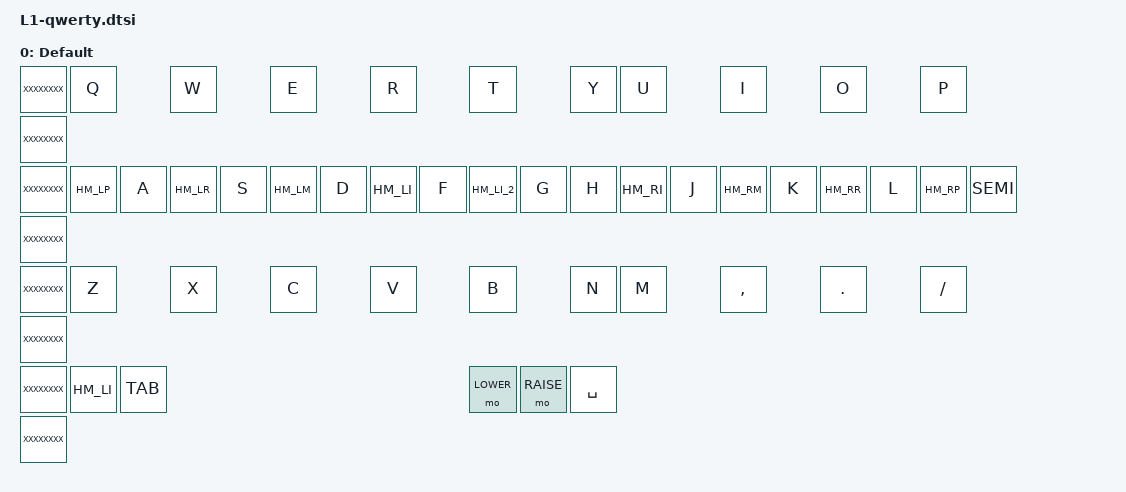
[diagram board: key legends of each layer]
/**
 *
 */

/ {
  keymap {
    compatible = "zmk,keymap";

	default_layer {
		label = "Default";
        bindings = <
//					╭───────────────┬───────────────┬───────────────┬───────────────┬───────────────╮   ╭───────────────┬───────────────┬───────────────┬───────────────┬───────────────╮
	XXXXXXXX			&kp Q           &kp W           &kp E           &kp R           &kp T               &kp Y           &kp U           &kp I           &kp O           &kp P
	XXXXXXXX	//	├───────────────┼───────────────┼───────────────┼───────────────┼───────────────┤   ├───────────────├───────────────┼───────────────┼───────────────┼───────────────┤
	XXXXXXXX			HM_LP A      	HM_LR S       	HM_LM D      	HM_LI F      	HM_LI_2 G               &kp H           HM_RI J     	HM_RM K   		HM_RR L      	HM_RP SEMI
	XXXXXXXX	//	├───────────────┼───────────────┼───────────────┼───────────────┼───────────────┤   ├───────────────├───────────────┼───────────────┼───────────────┼───────────────┤
	XXXXXXXX			&kp Z     		&kp X      		&kp C      		&kp V       	&kp B               &kp N           &kp M       	&kp COMMA  		&kp DOT   		&kp FSLH
	XXXXXXXX	//	╰───────────────┴───────────────┼───────────────┼───────────────┼───────────────┤   ├───────────────├───────────────┼───────────────┼───────────────┴───────────────╯
	XXXXXXXX       														HM_LI TAB		&mo LOWER		&mo RAISE		&kp SPACE
//                                                                  ╰───────────────┴───────────────╯   ╰───────────────┴───────────────╯
	XXXXXXXX
			>;
		};
    };
};
